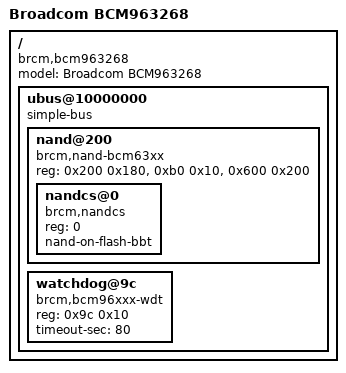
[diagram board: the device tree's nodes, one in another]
/*
 * Broadcom BCM63268 Reference Board DTS
 */

/dts-v1/;

#include "../bcm_963xx_template.dtsi"

/ {
	compatible = "brcm,bcm963268";
	model = "Broadcom BCM963268";

	/* Legacy UBUS base */
	ubus@10000000 {
		compatible = "simple-bus";
		ranges = <0 0x10000000 0x8000>;
		#address-cells = <1>;
		#size-cells = <1>;

		nand@200 {
			#address-cells = <1>;
			#size-cells = <0>;
			compatible = "brcm,nand-bcm63xx", "brcm,brcmnand-v4.0";
			reg = <0x200 0x180>, <0xb0 0x10>, <0x600 0x200>;
			reg-names = "nand", "nand-int-base", "nand-cache";
			status = "okay";

			nandcs@0 {
				compatible = "brcm,nandcs";
				reg = <0>;
				nand-on-flash-bbt;
			};

		};

		watchdog@9c {
			compatible = "brcm,bcm96xxx-wdt";
			reg = <0x9c 0x10>;
			timeout-sec = <80>;
		};
	};
};
